# STM32L475 register map
File version: 1.0
CPU: CM4 r0p1, little endian, MPU, FPU, 4 interrupt priority bits
Registers are 32-bit, read-write, reset 0x0 unless marked. A register's access mark holds for its fields unless they carry their own. Offsets are from the block's base; [hi:lo] are bit positions; lines under a group give offsets from that group; {n}, {i} and the like mark numbered series; 'fields as' and 'values as' point back to an identical list.

## CRC — Cyclic redundancy check calculation unit
Base 0x40023000
0x00 DR reset 0xFFFFFFFF — Data register
  [31:0] DR — Data register bits
0x04 IDR — Independent data register
  [7:0] IDR — General-purpose 8-bit data register bits
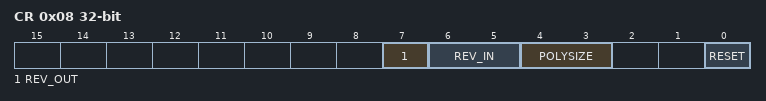
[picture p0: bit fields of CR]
0x08 CR access per field — Control register
  [7] REV_OUT rw — Reverse output data
  [6:5] REV_IN rw — Reverse input data
  [4:3] POLYSIZE rw — Polynomial size
  [0] RESET wo — RESET bit
0x10 INIT reset 0xFFFFFFFF — Initial CRC value
  [31:0] CRC_INIT — Programmable initial CRC value
0x14 POL reset 0x4C11DB7 — polynomial
  [31:0] Polynomialcoefficients — Programmable polynomial

## TSC — Touch sensing controller
Base 0x40024000
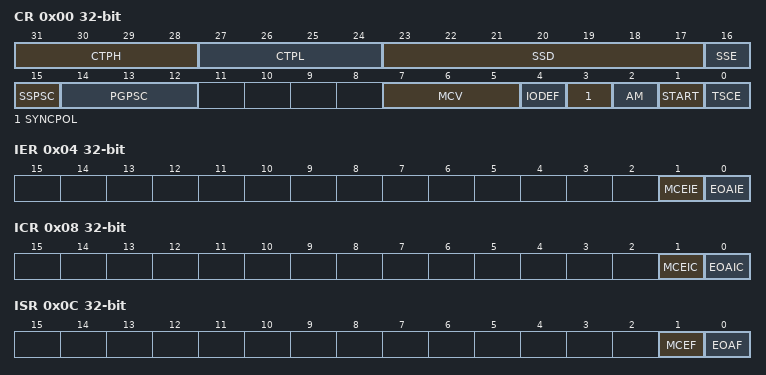
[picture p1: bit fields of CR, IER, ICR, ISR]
0x00 CR — control register
  [31:28] CTPH — Charge transfer pulse high
  [27:24] CTPL — Charge transfer pulse low
  [23:17] SSD — Spread spectrum deviation
  [16] SSE — Spread spectrum enable
  [15] SSPSC — Spread spectrum prescaler
  [14:12] PGPSC — pulse generator prescaler
  [7:5] MCV — Max count value
  [4] IODEF — I/O Default mode
  [3] SYNCPOL — Synchronization pin polarity
  [2] AM — Acquisition mode
  [1] START — Start a new acquisition
  [0] TSCE — Touch sensing controller enable
0x04 IER — interrupt enable register
  [1] MCEIE — Max count error interrupt enable
  [0] EOAIE — End of acquisition interrupt enable
0x08 ICR — interrupt clear register
  [1] MCEIC — Max count error interrupt clear
  [0] EOAIC — End of acquisition interrupt clear
0x0C ISR — interrupt status register
  [1] MCEF — Max count error flag
  [0] EOAF — End of acquisition flag
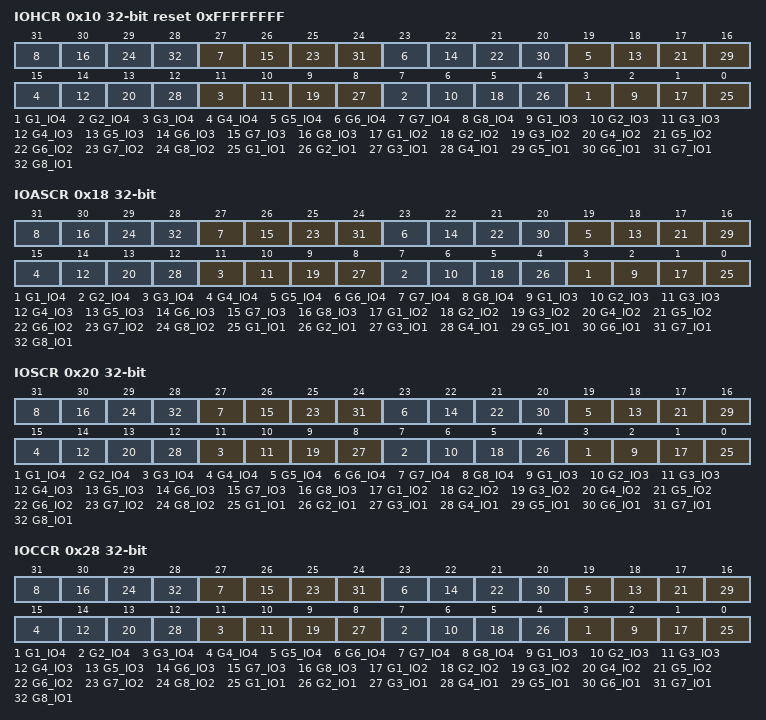
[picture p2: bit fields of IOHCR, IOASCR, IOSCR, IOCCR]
0x10 IOHCR reset 0xFFFFFFFF — I/O hysteresis control register
  [4n-1] G{n}_IO4 (n=1..8), [4n-2] G{n}_IO3 (n=1..8), [4n-3] G{n}_IO2 (n=1..8), [4n-4] G{n}_IO1 (n=1..8)
0x18 IOASCR — I/O analog switch control register
  fields as IOHCR
0x20 IOSCR — I/O sampling control register
  fields as IOHCR
0x28 IOCCR — I/O channel control register
  fields as IOHCR
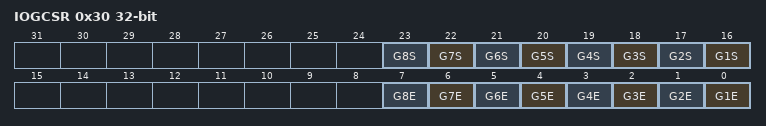
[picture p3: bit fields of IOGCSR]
0x30 IOGCSR access per field — I/O group control status register
  [n+15] G{n}S ro (n=1..8) — Analog I/O group x status
  [n-1] G{n}E rw (n=1..8) — Analog I/O group x enable
{0x30+4i} IOG{i}CR ro (i=1..8) — I/O group x counter register
  [13:0] CNT — Counter value

## IWDG — Independent watchdog
Base 0x40003000
0x00 KR wo — Key register
  [15:0] KEY — Key value (write only, read 0x0000)
0x04 PR — Prescaler register
  [2:0] PR — Prescaler divider
0x08 RLR reset 0xFFF — Reload register
  [11:0] RL — Watchdog counter reload value
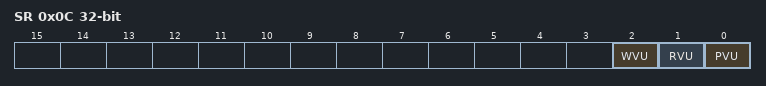
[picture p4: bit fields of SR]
0x0C SR ro — Status register
  [2] WVU — Watchdog counter window value update
  [1] RVU — Watchdog counter reload value update
  [0] PVU — Watchdog prescaler value update
0x10 WINR reset 0xFFF — Window register
  [11:0] WIN — Watchdog counter window value

## WWDG — System window watchdog
Base 0x40002C00
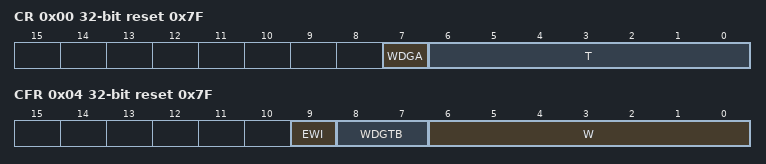
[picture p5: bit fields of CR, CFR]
0x00 CR reset 0x7F — Control register
  [7] WDGA — Activation bit
  [6:0] T — 7-bit counter (MSB to LSB)
0x04 CFR reset 0x7F — Configuration register
  [9] EWI — Early wakeup interrupt
  [8:7] WDGTB — Timer base
  [6:0] W — 7-bit window value
0x08 SR — Status register
  [0] EWIF — Early wakeup interrupt flag

## COMP — Comparator
Base 0x40010200
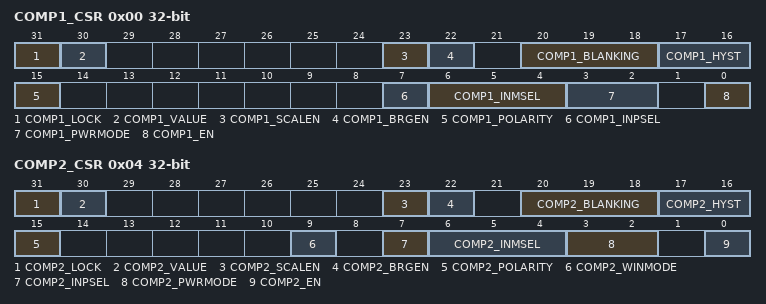
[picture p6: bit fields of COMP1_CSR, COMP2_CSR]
0x00 COMP1_CSR access per field — Comparator 1 control and status register
  [31] COMP1_LOCK wo — COMP1_CSR register lock bit
  [30] COMP1_VALUE ro — Comparator 1 output status bit
  [23] COMP1_SCALEN rw — Voltage scaler enable bit
  [22] COMP1_BRGEN rw — Scaler bridge enable
  [20:18] COMP1_BLANKING rw — Comparator 1 blanking source selection bits
  [17:16] COMP1_HYST rw — Comparator 1 hysteresis selection bits
  [15] COMP1_POLARITY rw — Comparator 1 polarity selection bit
  [7] COMP1_INPSEL rw — Comparator1 input plus selection bit
  [6:4] COMP1_INMSEL rw — Comparator 1 Input Minus connection configuration bit
  [3:2] COMP1_PWRMODE rw — Power Mode of the comparator 1
  [0] COMP1_EN rw — Comparator 1 enable bit
0x04 COMP2_CSR access per field — Comparator 2 control and status register
  [31] COMP2_LOCK wo — COMP2_CSR register lock bit
  [30] COMP2_VALUE ro — Comparator 2 output status bit
  [23] COMP2_SCALEN rw — Voltage scaler enable bit
  [22] COMP2_BRGEN rw — Scaler bridge enable
  [20:18] COMP2_BLANKING rw — Comparator 2 blanking source selection bits
  [17:16] COMP2_HYST rw — Comparator 2 hysteresis selection bits
  [15] COMP2_POLARITY rw — Comparator 2 polarity selection bit
  [9] COMP2_WINMODE rw — Windows mode selection bit
  [7] COMP2_INPSEL rw — Comparator 2 Input Plus connection configuration bit
  [6:4] COMP2_INMSEL rw — Comparator 2 Input Minus connection configuration bit
  [3:2] COMP2_PWRMODE rw — Power Mode of the comparator 2
  [0] COMP2_EN rw — Comparator 2 enable bit

## Notices in the file
Copyright (c) 2024 STMicroelectronics.
SPDX-License-Identifier: Apache-2.0
Licensed under the Apache License, Version 2.0 (the "License");
you may not use this file except in compliance with the License.
You may obtain a copy of the License at
http://www.apache.org/licenses/LICENSE-2.0
Unless required by applicable law or agreed to in writing, software
distributed under the License is distributed on an "AS IS" BASIS,
WITHOUT WARRANTIES OR CONDITIONS OF ANY KIND, either express or implied.
See the License for the specific language governing permissions and
limitations under the License.
